# CY8C5888LTI_LP097 register map
File version: 0.1
CY8C58LP
Registers are 8-bit, read-write, no defined reset value unless marked. A register's access mark holds for its fields unless they carry their own. Offsets are from the block's base; lines under a group give offsets from that group; [hi:lo] are bit positions; {n}, {i} and the like mark numbered series; 'fields as' and 'values as' point back to an identical list; <NAME> marks a mode.

## Memory map
0x00000000 RS485_CTS
0x00000000 UART_RS485 — UART

## RS485_CTS
Base 0x00000000
0x4000657A RS485_CTS_CONTROL_REG

## UART_RS485 — UART
Base 0x00000000
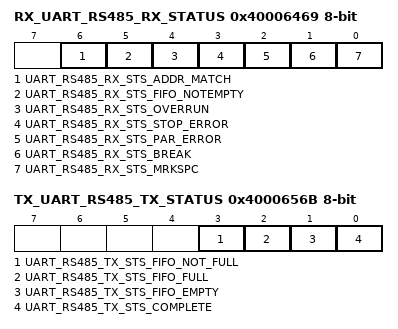
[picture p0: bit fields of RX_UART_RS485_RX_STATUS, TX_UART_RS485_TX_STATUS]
0x40006469 RX_UART_RS485_RX_STATUS — RX status register
  [6] UART_RS485_RX_STS_ADDR_MATCH ro, [5] UART_RS485_RX_STS_FIFO_NOTEMPTY ro, [4] UART_RS485_RX_STS_OVERRUN ro, [3] UART_RS485_RX_STS_STOP_ERROR ro, [2] UART_RS485_RX_STS_PAR_ERROR ro, [1] UART_RS485_RX_STS_BREAK ro, [0] UART_RS485_RX_STS_MRKSPC ro
0x4000652A RX_UART_RS485_RX_ADDRESS1 — RX Address1 Register
0x4000653A RX_UART_RS485_RX_ADDRESS2 — RX Address2 Register
0x40006548 TX_UART_RS485_TX_DATA — TX Data Register
0x4000654A RX_UART_RS485_RX_DATA — RX Data Register
0x4000656B TX_UART_RS485_TX_STATUS — TX status register
  [3] UART_RS485_TX_STS_FIFO_NOT_FULL ro, [2] UART_RS485_TX_STS_FIFO_FULL ro, [1] UART_RS485_TX_STS_FIFO_EMPTY ro, [0] UART_RS485_TX_STS_COMPLETE ro
